# STM32N655 register map
File version: 1.0
CPU: CM55 r0p1, little endian, no MPU, FPU, vendor SysTick, 8 interrupt priority bits
Registers are 32-bit, read-write, reset 0x0 unless marked. A register's access mark holds for its fields unless they carry their own. Offsets are from the block's base; [hi:lo] are bit positions; {n}, {i} and the like mark numbered series; 'fields as' and 'values as' point back to an identical list.

## GFXTIM — Graphic timer
Base 0x48004000
Same registers: GFXTIM_S 0x58004000
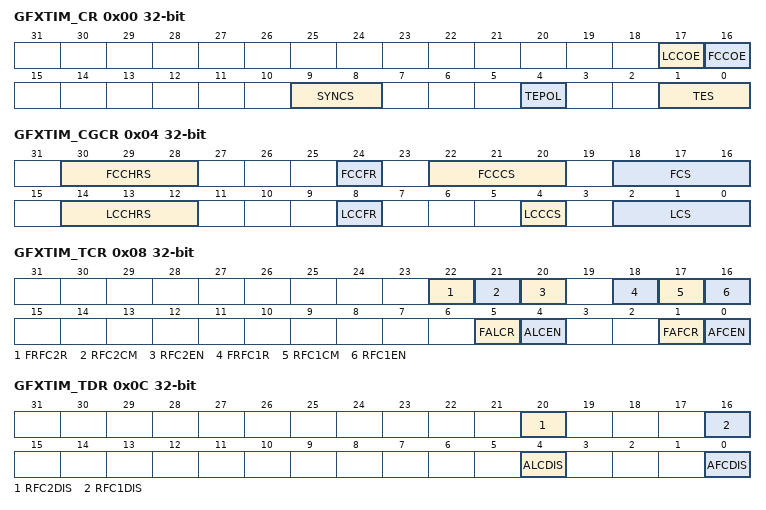
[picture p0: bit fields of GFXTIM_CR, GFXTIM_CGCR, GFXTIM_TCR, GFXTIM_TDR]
0x00 GFXTIM_CR — GFXTIM configuration register
  [17] LCCOE — line-clock calibration output enable
    0=line-clock output disabled; 1=line-clock output enabled
  [16] FCCOE — frame-clock calibration output enable
    0=frame-clock output disabled; 1=frame-clock output enabled
  [9:8] SYNCS — synchronization source
    {v}=gfxtim_hsync[{v}] and gfxtim_vsync[{v}] selected (v=0..3)
  [4] TEPOL — tearing--effect polarity
    0=tearing effect active on rising edge; 1=tearing effect active on falling edge
  [1:0] TES — tearing source
    0=TE input pad selected; 1=gfxtim_ite selected; 2=HSYNC input selected by SYNCS[1:0]; 3=VSYNC input selected by SYNCS[1:0]
0x04 GFXTIM_CGCR access per field — GFXTIM clock generator configuration register
  [30:28] FCCHRS rw — frame- -clock counter hardware reload source
    0=no hardware reload; 1=line- -clock counter underflow; 2=HSYNC rising edge; 3=HSYNC falling edge; 4=VSYNC rising edge; 5=VSYNC falling edge; 6=TE rising edge; 7=TE falling edge
  [24] FCCFR wo — frame clock counter force reload
    0=No effect; 1=frame clock counter reload forced
  [22:20] FCCCS rw — frame clock counter clock source
    0=frame clock counter disabled; 1=line clock counter underflow; 2=HSYNC rising edge; 3=HSYNC falling edge; 4=VSYNC rising edge; 5=VSYNC falling edge; 6=TE rising edge; 7=TE falling edge
  [18:16] FCS rw — frame clock source
    0=line clock counter underflow; 1=frame clock counter underflow; 2=HSYNC rising edge; 3=HSYNC falling edge; 4=VSYNC rising edge; 5=VSYNC falling edge; 6=TE rising edge; 7=TE falling edge
  [14:12] LCCHRS rw — line clock counter hardware reload source
    0=no hardware reload; 1=frame clock counter underflow; 2=HSYNC rising edge; 3=HSYNC falling edge; 4=VSYNC rising edge; 5=VSYNC falling edge; 6=TE rising edge; 7=TE falling edge
  [8] LCCFR wo — line clock counter force reload
    0=no effect; 1=line clock counter reload forced
  [4] LCCCS rw — line clock counter clock source
    0=line clock counter disabled; 1=system clock selected
  [2:0] LCS rw — line clock source
    values as FCS
0x08 GFXTIM_TCR access per field — GFXTIM timers configuration register
  [22] FRFC2R wo — force relative frame counter 2 reload
    0=no effect; 1=relative frame counter 2 reload forced
  [21] RFC2CM rw — relative frame counter 2 continuous mode
    0=relative frame counter 2 is one shot; 1=relative frame counter 2 is in continuous mode
  [20] RFC2EN wo — relative frame counter 2 enable
    0=no effect; 1=relative frame counter 2 enabled
  [18] FRFC1R wo — force relative frame counter 1 reload
    0=no effect; 1=relative frame counter 1 reload forced
  [17] RFC1CM rw — relative frame counter 1 continuous mode
    0=relative frame counter 1 is one shot; 1=relative frame counter 1 is in continuous mode
  [16] RFC1EN wo — relative frame counter 1 enable
    0=no effect; 1=relative frame counter enabled
  [5] FALCR wo — force absolute line counter reset
    0=no effect; 1=absolute line counter reset forced
  [4] ALCEN wo — absolute line counter enable
    0=no effect; 1=absolute line counter enabled
  [1] FAFCR wo — force absolute frame counter reset
    0=no effect; 1=absolute frame counter reset forced
  [0] AFCEN wo — absolute frame counter enable
    0=no effect; 1=absolute frame counter enabled
0x0C GFXTIM_TDR wo — GFXTIM timers disable register
  [20] RFC2DIS — relative frame counter 2 disable
    0=no effect; 1=relative frame counter 2 disabled
  [16] RFC1DIS — relative frame counter 1 disable
    0=no effect; 1=relative frame counter 1 disabled
  [4] ALCDIS — absolute line counter disable
    0=no effect; 1=absolute line counter disabled
  [0] AFCDIS — absolute frame counter disable
    0=no effect; 1=absolute frame counter disabled
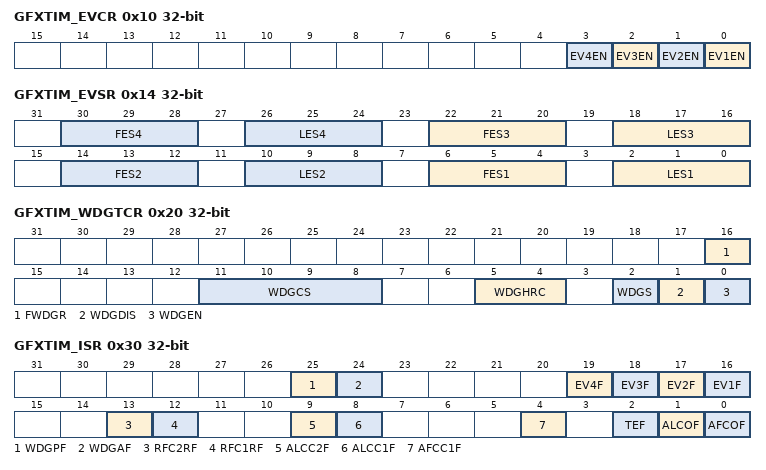
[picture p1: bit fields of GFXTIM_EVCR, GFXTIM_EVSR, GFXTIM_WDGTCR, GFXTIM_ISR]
0x10 GFXTIM_EVCR — GFXTIM events control register
  [n-1] EV{n}EN (n=1..4) — event {n} enable
    0=event {n} generation disabled; 1=event {n} generation enabled
0x14 GFXTIM_EVSR — GFXTIM events selection register
  [8n-2:8n-4] FES{n} (n=1..4) — frame-event selection {n}
    0=no frame event; 1=absolute frame counter overflow; 2=absolute frame counter compare; 4=relative frame counter 1 reload; 5=relative frame counter 2 reload
  [8n-6:8n-8] LES{n} (n=1..4) — line-event selection {n}
    0=no line event; 1=absolute line counter overflow; 2=tearing effect; 4=absolute line counter 1 compare; 5=absolute line counter 2 compare
0x20 GFXTIM_WDGTCR access per field — GFXTIM watchdog timer configuration register
  [16] FWDGR wo — force watchdog reload
    0=no effect; 1=graphic watchdog reload forced
  [11:8] WDGCS rw — watchdog clock source
    0=line clock; 1=frame clock; 2=HSYNC rising edge; 3=HSYNC falling edge; 4=VSYNC rising edge; 5=VSYNC falling edge; 6=TE rising edge; 7=TE falling edge; {v}=event {v-7} (v=8..11)
  [5:4] WDGHRC rw — watchdog hardware reload configuration
    0=watchdog hardware reload disabled; 1=watchdog reloaded a rising edge of gfxtim_wrld; 2=watchdog reloaded a falling edge of gfxtim_wrld
  [2] WDGS ro — watchdog status
    0=graphic watchdog disabled; 1=graphic watchdog enabled
  [1] WDGDIS wo — watchdog disable
    0=no effect; 1=graphic watchdog disabled
  [0] WDGEN wo — watchdog enable
    0=no effect; 1=graphic watchdog enabled
0x30 GFXTIM_ISR ro — GFXTIM interrupt status register
  [25] WDGPF — watchdog pre-alarm flag
    0=no graphic watchdog pre-alarm occurred; 1=a graphic watchdog pre-alarm occurred
  [24] WDGAF — watchdog alarm flag
    0=no graphic watchdog alarm occurred; 1=a graphic watchdog alarm occurred
  [19] EV4F — event 4 flag
    0=no complex event 4 occurred; 1=a complex event 4 occurred
  [18] EV3F — event 3 flag
    0=no complex event 3 occurred; 1=a complex event 3 occurred
  [17] EV2F — event 2 flag
    0=no complex event 2 occurred; 1=a complex event 2 occurred
  [16] EV1F — event 1 flag
    0=No complex event 1 occurred; 1=Complex event 1 occurred
  [13] RFC2RF — relative frame counter 2 reload flag
    0=no reload occurred on relative frame counter 2; 1=a reload on relative frame counter 2 occurred
  [12] RFC1RF — relative frame counter 1 reload flag
    0=no reload occurred on relative frame counter 1; 1=a reload on relative frame counter 1 occurred
  [9] ALCC2F — absolute line counter compare 2 flag
    0=no match occurred on compare 2 of the absolute line counter; 1=a match on compare 2 of the absolute line counter occurred
  [8] ALCC1F — absolute line counter compare 1 flag
    0=no match occurred on compare 1 of the absolute line counter; 1=a match on compare 1 of the absolute line counter occurred
  [4] AFCC1F — absolute frame counter compare 1 flag
    0=no match occurred on compare 1 of the absolute frame counter; 1=a match on compare 1 of the absolute frame counter occurred
  [2] TEF — tearing-effect flag
    0=no tearing effect occurred; 1=a tearing effect occurred
  [1] ALCOF — absolute line counter overflow flag
    0=no overflow occurred on the absolute line counter; 1=a overflow on the absolute line counter occurred
  [0] AFCOF — absolute frame counter overflow flag
    0=no overflow occurred on the absolute frame counter; 1=a overflow on the absolute frame counter occurred
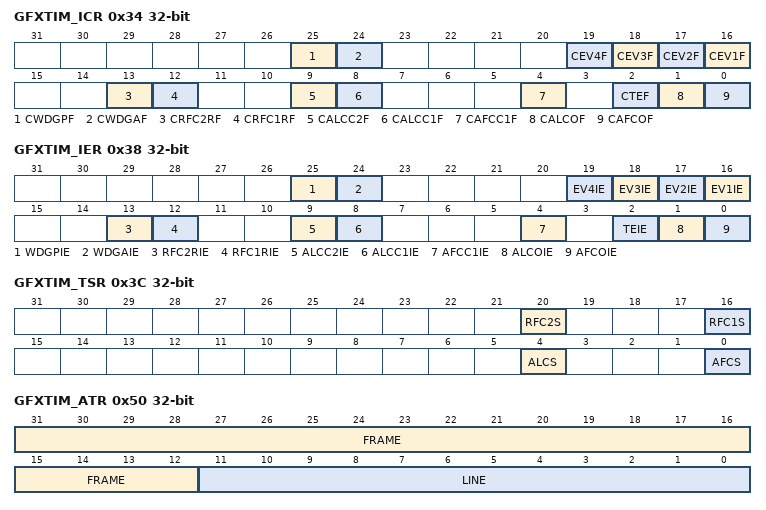
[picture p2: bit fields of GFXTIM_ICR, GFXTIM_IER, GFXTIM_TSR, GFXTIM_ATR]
0x34 GFXTIM_ICR wo — GFXTIM interrupt clear register
  [25] CWDGPF — clear watchdog pre-alarm flag
    0=no effect; 1=WDGPF cleared
  [24] CWDGAF — clear watchdog alarm flag
    0=no effect; 1=WDGAF cleared
  [n+15] CEV{n}F (n=1..4) — clear event {n} flag
    0=no effect; 1=EV{n}F cleared
  [13] CRFC2RF — clear relative frame counter 2 reload flag
    0=no effect; 1=RFC2RF cleared
  [12] CRFC1RF — clear relative frame counter 1 reload flag
    0=no effect; 1=RFC1RF cleared
  [9] CALCC2F — clear absolute line counter compare 2 flag
    0=no effect; 1=ALCC2F cleared
  [8] CALCC1F — clear absolute line counter compare 1 flag
    0=no effect; 1=ALCC1F cleared
  [4] CAFCC1F — clear absolute frame counter compare 1 flag
    0=no effect; 1=AFCC1F cleared
  [2] CTEF — clear tearing-effect flag
    0=no effect; 1=TEF cleared
  [1] CALCOF — clear absolute line counter overflow flag
    0=no effect; 1=ALCOF cleared
  [0] CAFCOF — clear absolute frame counter overflow flag
    0=no effect; 1=AFCOF cleared
0x38 GFXTIM_IER — GFXTIM interrupt enable register
  [25] WDGPIE — watchdog pre-alarm interrupt enable
    0=watchdog pre-alarm interrupt disabled; 1=watchdog pre-alarm interrupt enabled
  [24] WDGAIE — watchdog alarm interrupt enable
    0=watchdog alarm interrupt disabled; 1=watchdog alarm interrupt enabled
  [n+15] EV{n}IE (n=1..4) — event {n} interrupt enable
    0=event {n} interrupt disabled; 1=event {n} interrupt enabled
  [13] RFC2RIE — relative frame counter 2 reload interrupt enable
    0=relative frame counter 2 reload interrupt disabled; 1=relative frame counter 2 reload interrupt enabled
  [12] RFC1RIE — relative frame counter 1 reload interrupt enable
    0=relative frame counter 1 reload interrupt disabled; 1=relative frame counter 1 reload interrupt enabled
  [9] ALCC2IE — absolute line counter compare 2 interrupt enable
    0=absolute line counter compare 2 interrupt disabled; 1=absolute line counter compare 2 interrupt enabled
  [8] ALCC1IE — absolute line counter compare 1 interrupt enable
    0=absolute line counter compare 1 interrupt disabled; 1=absolute line counter compare 1 interrupt enabled
  [4] AFCC1IE — absolute frame counter compare 1 interrupt enable
    0=absolute frame counter compare 1 interrupt disabled; 1=absolute frame counter compare 1 interrupt enabled
  [2] TEIE — tearing-effect interrupt enable
    0=tearing-effect interrupt disabled; 1=tearing-effect interrupt enabled
  [1] ALCOIE — absolute line counter overflow interrupt enable
    0=absolute line counter overflow interrupt disabled; 1=absolute line counter overflow interrupt enabled
  [0] AFCOIE — absolute frame counter overflow interrupt enable
    0=absolute frame counter overflow interrupt disabled; 1=absolute frame counter overflow interrupt enabled
0x3C GFXTIM_TSR ro — GFXTIM timers status register
  [20] RFC2S — relative frame counter 2 status
    0=relative frame counter 2 disabled; 1=relative frame counter 2 enabled
  [16] RFC1S — relative frame counter 1 status
    0=relative frame counter 1 disabled; 1=relative frame counter 1 enabled
  [4] ALCS — absolute line counter status
    0=absolute line counter disabled; 1=absolute line counter enabled
  [0] AFCS — absolute frame counter status
    0=absolute frame counter disabled; 1=absolute frame counter enabled
0x40 GFXTIM_LCCRR — GFXTIM line clock counter reload register
  [21:0] RELOAD — reload value
0x44 GFXTIM_FCCRR — GFXTIM frame clock counter reload register
  [11:0] RELOAD — reload value
0x50 GFXTIM_ATR ro — GFXTIM absolute time register
  [31:12] FRAME — fame number
  [11:0] LINE — line number
0x54 GFXTIM_AFCR — GFXTIM absolute frame counter register
  [19:0] FRAME — frame number
0x58 GFXTIM_ALCR — GFXTIM absolute line counter register
  [11:0] LINE — line number
0x60 GFXTIM_AFCC1R — GFXTIM absolute frame counter compare 1 register
  [19:0] FRAME — frame number
0x70 GFXTIM_ALCC1R — GFXTIM absolute line counter compare 1 register
  [11:0] LINE — line number
0x74 GFXTIM_ALCC2R — GFXTIM absolute line counter compare 2 register
  [11:0] LINE — line number
0x80 GFXTIM_RFC1R ro — GFXTIM relative frame counter 1 register
  [11:0] FRAME — frame number
0x84 GFXTIM_RFC1RR — GFXTIM relative frame counter 1 reload register
  [11:0] FRAME — frame reload value
0x88 GFXTIM_RFC2R ro — GFXTIM relative frame counter 2 register
  [11:0] FRAME — frame number
0x8C GFXTIM_RFC2RR — GFXTIM relative frame counter 2 reload register
  [11:0] FRAME — frame reload value
0xA0 GFXTIM_WDGCR ro — GFXTIM watchdog counter register
  [15:0] VALUE
0xA4 GFXTIM_WDGRR — GFXTIM watchdog reload register
  [15:0] RELOAD — reload value
0xA8 GFXTIM_WDGPAR — GFXTIM watchdog pre-alarm register
  [15:0] PREALARM — pre-alarm value
